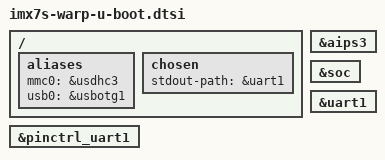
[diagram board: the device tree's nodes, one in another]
/ {
    aliases {
        mmc0 = &usdhc3;
        usb0 = &usbotg1;
    };

    chosen {
        stdout-path = &uart1;
    };
};

&aips3 {
	u-boot,dm-all;
};

&pinctrl_uart1 {
	u-boot,dm-all;
};

&soc {
	u-boot,dm-all;
};

&uart1 {
	u-boot,dm-all;
};
